# AVR32LA32 register map
Vendor: Atmel; File version: 1.0
CPU: other r0p0, little endian, no MPU, no FPU, 4 interrupt priority bits
Registers are 8-bit, read-write, reset 0x0 unless marked. A register's access mark holds for its fields unless they carry their own. Offsets are from the block's base; [hi:lo] are bit positions; 'fields as' and 'values as' point back to an identical list.

## TWI0 — Two-Wire Interface
Base 0x00800900
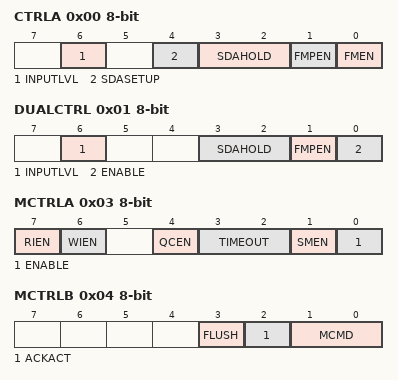
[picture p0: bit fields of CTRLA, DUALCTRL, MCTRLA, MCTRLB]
0x00 CTRLA — Control A
  [6] INPUTLVL — Input voltage transition level
    0=I2C (I2C input voltage transition level); 1=SMBUS (SMBus 3.0 input voltage transition level)
  [4] SDASETUP — SDA Setup Time
    0=4CYC (SDA setup time is four clock cycles); 1=8CYC (SDA setup time is eight clock cycle)
  [3:2] SDAHOLD — SDA Hold Time
    0=OFF (No SDA Hold Delay); 1=50NS (Short SDA hold time); 2=300NS (Meets SMBUS 2.0 specification under typical conditions); 3=500NS (Meets SMBUS 2.0 specificaiton across all corners)
  [1] FMPEN — Fast-mode Plus Enable
    0=OFF (Operating in Standard-mode or Fast-mode); 1=ON (Operating in Fast-mode Plus)
  [0] FMEN — Fast-mode Enable
    0=OFF (SCL duty cycle operating according to Sm specification); 1=ON (SCL duty cycle operating according to Fm specification)
0x01 DUALCTRL — Dual Mode Control
  [6] INPUTLVL — Input voltage transition level
    values as CTRLA.INPUTLVL
  [3:2] SDAHOLD — SDA Hold Time
    values as CTRLA.SDAHOLD
  [1] FMPEN — Fast-mode Plus Enable
    values as CTRLA.FMPEN
  [0] ENABLE
0x02 DBGCTRL — Debug Control
  [0] DBGRUN — Debug Run
    0=HALT (The peripheral is halted in Break Debug mode and ignores events); 1=RUN (The peripheral will continue to run in Break Debug mode when the CPU is halted)
0x03 MCTRLA — Host Control A
  [7] RIEN — Read Interrupt Enable
  [6] WIEN — Write Interrupt Enable
  [4] QCEN — Quick Command Enable
  [3:2] TIMEOUT — Inactive Bus Time-Out
    0=DISABLED (Bus time-out disabled. I2C.); 1=50US (50us - SMBus); 2=100US; 3=200US
  [1] SMEN — Smart Mode Enable
  [0] ENABLE
0x04 MCTRLB — Host Control B
  [3] FLUSH
  [2] ACKACT — Acknowledge Action
    0=ACK (Send ACK); 1=NACK (Send NACK)
  [1:0] MCMD — Command
    0=NOACT (No action); 1=REPSTART (Execute Acknowledge Action followed by repeated Start.); 2=RECVTRANS (Execute Acknowledge Action followed by a byte read/write operation. Read/write is defined by DIR.); 3=STOP (Execute Acknowledge Action followed by issuing a Stop condition.)
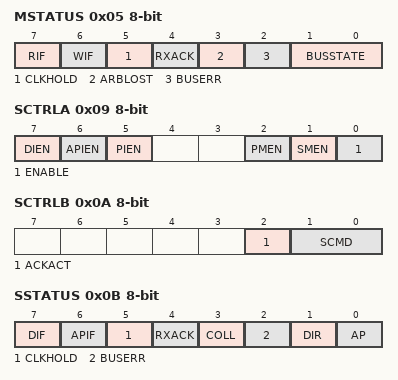
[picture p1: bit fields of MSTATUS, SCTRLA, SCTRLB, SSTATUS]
0x05 MSTATUS — Host STATUS
  [7] RIF — Read Interrupt Flag
  [6] WIF — Write Interrupt Flag
  [5] CLKHOLD — Clock Hold
  [4] RXACK ro — Received Acknowledge
  [3] ARBLOST — Arbitration Lost
  [2] BUSERR — Bus Error
  [1:0] BUSSTATE
    0=UNKNOWN (Unknown bus state); 1=IDLE (Bus is idle); 2=OWNER (This TWI controls the bus); 3=BUSY (The bus is busy)
0x06 MBAUD — Host Baud Rate
  [7:0] BAUD — Baud Rate
0x07 MADDR — Host Address
  [7:0] ADDR — Address
0x08 MDATA — Host Data
  [7:0] DATA
0x09 SCTRLA — Client Control A
  [7] DIEN — Data Interrupt Enable
  [6] APIEN — Address or Stop Interrupt Enable
  [5] PIEN — Stop Interrupt Enable
  [2] PMEN — Address Recognition Mode
  [1] SMEN — Smart Mode Enable
  [0] ENABLE
0x0A SCTRLB — Client Control B
  [2] ACKACT — Acknowledge Action
    0=ACK (Send ACK); 1=NACK (Send NACK)
  [1:0] SCMD — Command
    0=NOACT (No Action); 2=COMPTRANS (Complete transaction); 3=RESPONSE (Used in response to an interrupt)
0x0B SSTATUS — Client Status
  [7] DIF ro — Data Interrupt Flag
  [6] APIF ro — Address or Stop Interrupt Flag
  [5] CLKHOLD ro — Clock Hold
  [4] RXACK ro — Received Acknowledge
  [3] COLL — Collision
  [2] BUSERR — Bus Error
  [1] DIR ro — Read/Write Direction
  [0] AP ro — Address or Stop
    0=STOP (A Stop condition generated the interrupt on APIF flag); 1=ADR (Address detection generated the interrupt on APIF flag)
0x0C SADDR — Client Address
  [7:0] ADDR — Address
0x0D SDATA — Client Data
  [7:0] DATA
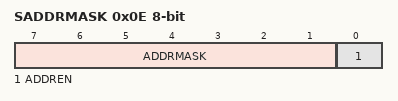
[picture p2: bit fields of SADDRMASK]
0x0E SADDRMASK — Client Address Mask
  [7:1] ADDRMASK — Address Mask
  [0] ADDREN — Address Mask Enable

## VPORTA — Virtual Ports
Base 0x00800000
Same registers: VPORTC 0x00800008, VPORTD 0x0080000C, VPORTF 0x00800014
0x00 DIR — Data Direction
0x01 OUT — Output Value
0x02 IN — Input Value
0x03 INTFLAGS — Interrupt Flags
  [7:0] INT — Pin Interrupt Flag

## VREF — Voltage reference
Base 0x008000B4
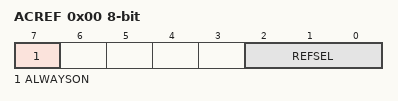
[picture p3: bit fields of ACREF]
0x00 ACREF — AC Reference
  [7] ALWAYSON
  [2:0] REFSEL — Reference select
    0=1V024 (Internal 1.024V reference); 1=2V048 (Internal 2.048V reference); 2=4V096 (Internal 4.096V reference); 3=2V500 (Internal 2.500V reference); 5=VDD (VDD as reference); 6=EXTVREF (External reference from EXTVREF0 pin)

## WDT — Watch-Dog Timer
Base 0x00800100
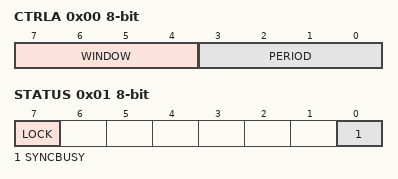
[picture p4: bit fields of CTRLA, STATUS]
0x00 CTRLA — Control A
  [7:4] WINDOW
    0=OFF; 1=8CLK (8 cycles (8ms)); 2=16CLK (16 cycles (16ms)); 3=32CLK (32 cycles (32ms)); 4=64CLK (64 cycles (64ms)); 5=128CLK (128 cycles (0.128s)); 6=256CLK (256 cycles (0.256s)); 7=512CLK (512 cycles (0.512s)); 8=1KCLK (1K cycles (1.0s)); 9=2KCLK (2K cycles (2.0s)); 10=4KCLK (4K cycles (4.1s)); 11=8KCLK (8K cycles (8.2s))
  [3:0] PERIOD
    values as WINDOW
0x01 STATUS
  [7] LOCK — Lock enable
  [0] SYNCBUSY ro — Syncronization busy
